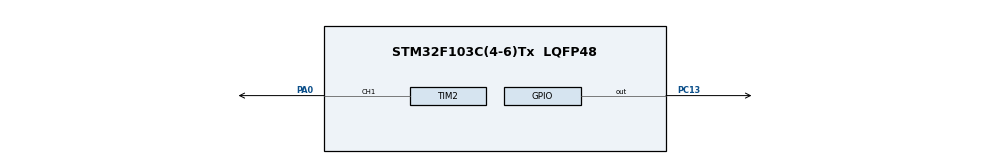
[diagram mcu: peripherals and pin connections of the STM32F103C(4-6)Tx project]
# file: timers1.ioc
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Mcu.Family=STM32F1
Mcu.Name=STM32F103C(4-6)Tx
Mcu.Package=LQFP48
NVIC.PriorityGroup=NVIC_PRIORITYGROUP_4
NVIC.TIM2_IRQn=true\:0\:0\:false\:false\:true\:true\:true\:true
PA0-WKUP.Signal=S_TIM2_CH1_ETR
PA13.Mode=Serial_Wire
PA13.Signal=SYS_JTMS-SWDIO
PA14.Mode=Serial_Wire
PA14.Signal=SYS_JTCK-SWCLK
PC13-TAMPER-RTC.Signal=GPIO_Output
PD0-OSC_IN.Mode=HSE-External-Oscillator
PD0-OSC_IN.Signal=RCC_OSC_IN
PD1-OSC_OUT.Mode=HSE-External-Oscillator
PD1-OSC_OUT.Signal=RCC_OSC_OUT
ProjectManager.HeapSize=0x200
ProjectManager.StackSize=0x400
ProjectManager.TargetToolchain=STM32CubeIDE
RCC.APB1Freq_Value=8000000
RCC.APB2Freq_Value=8000000
RCC.SYSCLKSource=RCC_SYSCLKSOURCE_PLLCLK
SH.S_TIM2_CH1_ETR.0=TIM2_CH1,PWM Generation1 CH1
TIM2.Channel-PWM\ Generation1\ CH1=TIM_CHANNEL_1
TIM2.Period=1000
TIM2.Prescaler=7
VP_TIM2_VS_ClockSourceINT.Mode=Internal
board=custom

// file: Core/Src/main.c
/* USER CODE BEGIN Header */
/**
  ******************************************************************************
  * @file           : main.c
  * @brief          : Main program body
  ******************************************************************************
  * @attention
  *
  * Copyright (c) 2026 STMicroelectronics.
  * All rights reserved.
  *
  * This software is licensed under terms that can be found in the LICENSE file
  * in the root directory of this software component.
  * If no LICENSE file comes with this software, it is provided AS-IS.
  *
  ******************************************************************************
  */
/* USER CODE END Header */
#include "main.h"

/* USER CODE BEGIN Includes */
#include <stdio.h>
/* USER CODE END Includes */

TIM_HandleTypeDef htim2;

/* USER CODE BEGIN PV */
volatile int lolol = 0;
/* USER CODE END PV */

void SystemClock_Config(void);
static void MX_GPIO_Init(void);
static void MX_TIM2_Init(void);

int main(void)
{

  /* MCU Configuration--------------------------------------------------------*/

  /* Reset of all peripherals, Initializes the Flash interface and the Systick. */
  HAL_Init();

  /* Configure the system clock */
  SystemClock_Config();

  /* Initialize all configured peripherals */
  MX_GPIO_Init();
  MX_TIM2_Init();

  /* Infinite loop */
  /* USER CODE BEGIN WHILE */
  HAL_TIM_Base_Start(&htim2);
  HAL_TIM_PWM_Init(&htim2);
  HAL_TIM_PWM_Start(&htim2, TIM_CHANNEL_1);
  while (1)
  {
    /* USER CODE END WHILE */

    /* USER CODE BEGIN 3 */
	  for(int i = 0; i < 1000; i++)
	  {
		  htim2.Instance->CCR1 = i;
		  HAL_Delay(1);
	  }
	  for(int i = 1000; i > 0; i--)
	  {
		  htim2.Instance->CCR1 = i;
		  HAL_Delay(1);
	  }
  }
  /* USER CODE END 3 */
}

void SystemClock_Config(void)
{
  RCC_OscInitTypeDef RCC_OscInitStruct = {0};
  RCC_ClkInitTypeDef RCC_ClkInitStruct = {0};

  /** Initializes the RCC Oscillators according to the specified parameters
  * in the RCC_OscInitTypeDef structure.
  */
  RCC_OscInitStruct.OscillatorType = RCC_OSCILLATORTYPE_HSI;
  RCC_OscInitStruct.HSIState = RCC_HSI_ON;
  RCC_OscInitStruct.HSICalibrationValue = RCC_HSICALIBRATION_DEFAULT;
  RCC_OscInitStruct.PLL.PLLState = RCC_PLL_ON;
  RCC_OscInitStruct.PLL.PLLSource = RCC_PLLSOURCE_HSI_DIV2;
  RCC_OscInitStruct.PLL.PLLMUL = RCC_PLL_MUL2;
  if (HAL_RCC_OscConfig(&RCC_OscInitStruct) != HAL_OK)
  {
    Error_Handler();
  }

  /** Initializes the CPU, AHB and APB buses clocks
  */
  RCC_ClkInitStruct.ClockType = RCC_CLOCKTYPE_HCLK|RCC_CLOCKTYPE_SYSCLK
                              |RCC_CLOCKTYPE_PCLK1|RCC_CLOCKTYPE_PCLK2;
  RCC_ClkInitStruct.SYSCLKSource = RCC_SYSCLKSOURCE_PLLCLK;
  RCC_ClkInitStruct.AHBCLKDivider = RCC_SYSCLK_DIV1;
  RCC_ClkInitStruct.APB1CLKDivider = RCC_HCLK_DIV1;
  RCC_ClkInitStruct.APB2CLKDivider = RCC_HCLK_DIV1;

  if (HAL_RCC_ClockConfig(&RCC_ClkInitStruct, FLASH_LATENCY_0) != HAL_OK)
  {
    Error_Handler();
  }
}

static void MX_TIM2_Init(void)
{

  TIM_ClockConfigTypeDef sClockSourceConfig = {0};
  TIM_MasterConfigTypeDef sMasterConfig = {0};
  TIM_OC_InitTypeDef sConfigOC = {0};

  htim2.Instance = TIM2;
  htim2.Init.Prescaler = 7;
  htim2.Init.CounterMode = TIM_COUNTERMODE_UP;
  htim2.Init.Period = 1000;
  htim2.Init.ClockDivision = TIM_CLOCKDIVISION_DIV1;
  htim2.Init.AutoReloadPreload = TIM_AUTORELOAD_PRELOAD_DISABLE;
  if (HAL_TIM_Base_Init(&htim2) != HAL_OK)
  {
    Error_Handler();
  }
  sClockSourceConfig.ClockSource = TIM_CLOCKSOURCE_INTERNAL;
  if (HAL_TIM_ConfigClockSource(&htim2, &sClockSourceConfig) != HAL_OK)
  {
    Error_Handler();
  }
  if (HAL_TIM_PWM_Init(&htim2) != HAL_OK)
  {
    Error_Handler();
  }
  sMasterConfig.MasterOutputTrigger = TIM_TRGO_RESET;
  sMasterConfig.MasterSlaveMode = TIM_MASTERSLAVEMODE_DISABLE;
  if (HAL_TIMEx_MasterConfigSynchronization(&htim2, &sMasterConfig) != HAL_OK)
  {
    Error_Handler();
  }
  sConfigOC.OCMode = TIM_OCMODE_PWM1;
  sConfigOC.Pulse = 0;
  sConfigOC.OCPolarity = TIM_OCPOLARITY_HIGH;
  sConfigOC.OCFastMode = TIM_OCFAST_DISABLE;
  if (HAL_TIM_PWM_ConfigChannel(&htim2, &sConfigOC, TIM_CHANNEL_1) != HAL_OK)
  {
    Error_Handler();
  }
  HAL_TIM_MspPostInit(&htim2);

}

static void MX_GPIO_Init(void)
{
  GPIO_InitTypeDef GPIO_InitStruct = {0};

  /* GPIO Ports Clock Enable */
  __HAL_RCC_GPIOC_CLK_ENABLE();
  __HAL_RCC_GPIOD_CLK_ENABLE();
  __HAL_RCC_GPIOA_CLK_ENABLE();

  /*Configure GPIO pin Output Level */
  HAL_GPIO_WritePin(GPIOC, GPIO_PIN_13, GPIO_PIN_RESET);

  /*Configure GPIO pin : PC13 */
  GPIO_InitStruct.Pin = GPIO_PIN_13;
  GPIO_InitStruct.Mode = GPIO_MODE_OUTPUT_PP;
  GPIO_InitStruct.Pull = GPIO_NOPULL;
  GPIO_InitStruct.Speed = GPIO_SPEED_FREQ_LOW;
  HAL_GPIO_Init(GPIOC, &GPIO_InitStruct);

}

void Error_Handler(void)
{
  __disable_irq();
  while (1)
  {
  }
}
